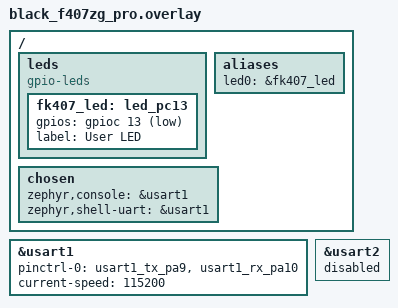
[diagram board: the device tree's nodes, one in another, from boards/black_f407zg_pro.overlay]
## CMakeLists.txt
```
cmake_minimum_required(VERSION 3.20.0)

find_package(Zephyr REQUIRED HINTS $ENV{ZEPHYR_BASE})
project(fk407m2_blinky_uart_usbh_msc)

# This app links the SAME shared app/ + external/ sources (two levels up,
# repo root) as the host/freertos/threadx targets - only this directory's
# own concrete adapters (OSAL: osal.c, cfuture_sync_ops.c; PAL: log_sink_impl.c,
# time_source_impl.c, board_led.c, usb_host_irq.c, hal_shim.c, crash_dump_zephyr.c)
# and src/main.c (composition root) are Zephyr-specific. usb_host.c/usbh_conf.c
# used to be a near-duplicate per target too; they're shared app/ sources now -
# only IRQ registration (usb_host_irq.c) and the heap (osal.c's
# osal_malloc()/osal_free()) still differ per platform.
set(APP_ROOT ${CMAKE_CURRENT_SOURCE_DIR}/../..)
set(SHARED_APP_DIR ${APP_ROOT}/app)
set(SHARED_EXTERNAL_DIR ${APP_ROOT}/external)
set(OSAL_DIR ${CMAKE_CURRENT_SOURCE_DIR}/osal)
set(PAL_DIR ${CMAKE_CURRENT_SOURCE_DIR}/pal)

# Zephyr's own hal_stm32 module vendors this SoC's HAL/LL sources but only
# compiles the subset its own drivers reference (see CLAUDE.md for why). We
# add exactly the files this app's USB Host MSC + FatFS showcase needs
# directly to `app`, alongside the app's own sources.
set(HAL_STM32_F4XX_DIR $ENV{ZEPHYR_BASE}/../modules/hal/stm32/stm32cube/stm32f4xx)

target_sources(app PRIVATE
    src/main.c
    osal/src/osal.c
    osal/src/cfuture_sync_ops.c
    pal/src/board_led.c
    pal/src/log_sink_impl.c
    pal/src/time_source_impl.c
    pal/src/hal_shim.c
    pal/src/usb_host_irq.c
    pal/src/crash_dump_zephyr.c

    # Shared OS-agnostic application layer (identical across every target)
    ${SHARED_APP_DIR}/src/core/app.c
    ${SHARED_APP_DIR}/src/core/app_threads.c
    ${SHARED_APP_DIR}/src/core/logger.c
    ${SHARED_APP_DIR}/src/diagnostics/app_task_trace.c
    ${SHARED_APP_DIR}/src/diagnostics/blinky_task.c
    ${SHARED_APP_DIR}/src/diagnostics/cfuture_selftest.c
    ${SHARED_APP_DIR}/src/diagnostics/crash_dump.c
    ${SHARED_APP_DIR}/src/storage/storage_service.c
    ${SHARED_APP_DIR}/src/storage/client_tasks.c
    ${SHARED_APP_DIR}/src/storage/storage_demo.c
    ${SHARED_APP_DIR}/src/storage/fatfs_diskio.c
    ${SHARED_APP_DIR}/src/storage/fatfs_time.c
    ${SHARED_APP_DIR}/src/usb/usbh_msc_disk.c
    ${SHARED_APP_DIR}/src/usb/usb_host.c
    ${SHARED_APP_DIR}/src/usb/usbh_conf.c

    # Vendored ST HAL (HCD + GPIO + Cortex/NVIC - see CLAUDE.md)
    ${HAL_STM32_F4XX_DIR}/drivers/src/stm32f4xx_hal_hcd.c
    ${HAL_STM32_F4XX_DIR}/drivers/src/stm32f4xx_ll_usb.c
    ${HAL_STM32_F4XX_DIR}/drivers/src/stm32f4xx_hal_gpio.c
    ${HAL_STM32_F4XX_DIR}/drivers/src/stm32f4xx_hal_cortex.c

    # Shared vendored ST USB Host Core + MSC class library
    ${SHARED_EXTERNAL_DIR}/usb_host_lib/Core/Src/usbh_core.c
    ${SHARED_EXTERNAL_DIR}/usb_host_lib/Core/Src/usbh_ctlreq.c
    ${SHARED_EXTERNAL_DIR}/usb_host_lib/Core/Src/usbh_ioreq.c
    ${SHARED_EXTERNAL_DIR}/usb_host_lib/Core/Src/usbh_pipes.c
    ${SHARED_EXTERNAL_DIR}/usb_host_lib/Class/MSC/Src/usbh_msc.c
    ${SHARED_EXTERNAL_DIR}/usb_host_lib/Class/MSC/Src/usbh_msc_bot.c
    ${SHARED_EXTERNAL_DIR}/usb_host_lib/Class/MSC/Src/usbh_msc_scsi.c

    # Shared vendored Chan's FatFS (_USE_LFN == 0 in this project's
    # ffconf.h - no long-filename support, so option/ffunicode.c is not needed)
    ${SHARED_EXTERNAL_DIR}/fatfs/src/ff.c

    # Shared vendored libcfuture
    ${SHARED_EXTERNAL_DIR}/cfuture/src/cfuture.c
    ${SHARED_EXTERNAL_DIR}/cfuture/src/cfuture_pal.c
)

target_include_directories(app PRIVATE
    ${OSAL_DIR}/include
    ${PAL_DIR}/include
    ${SHARED_APP_DIR}/include
    ${SHARED_APP_DIR}/include/osal
    ${SHARED_APP_DIR}/include/pal
    ${SHARED_APP_DIR}/include/core
    ${SHARED_APP_DIR}/include/diagnostics
    ${SHARED_APP_DIR}/include/storage
    ${SHARED_APP_DIR}/include/usb
    ${SHARED_EXTERNAL_DIR}/cfuture/include
    ${SHARED_EXTERNAL_DIR}/fatfs
    ${SHARED_EXTERNAL_DIR}/fatfs/src
    ${SHARED_EXTERNAL_DIR}/usb_host_lib/Core/Inc
    ${SHARED_EXTERNAL_DIR}/usb_host_lib/Class/MSC/Inc
    ${HAL_STM32_F4XX_DIR}/drivers/include
    ${HAL_STM32_F4XX_DIR}/soc
    $ENV{ZEPHYR_BASE}/../modules/hal/cmsis/CMSIS/Core/Include
)

target_compile_definitions(app PRIVATE
    STM32F407xx
    USE_HAL_DRIVER
)
```

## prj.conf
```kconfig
CONFIG_GPIO=y
CONFIG_SERIAL=y
CONFIG_CONSOLE=y
CONFIG_UART_CONSOLE=y
CONFIG_PRINTK=y

# osal_zephyr.c dynamically allocates per-task stacks (k_thread_stack_alloc)
# and per-queue k_msgq control blocks/buffers (k_malloc/k_msgq_alloc_init) -
# mirrors osal_threadx.c's own use of ThreadX's byte pool for the same
# purpose. Raw stack requests alone total ~36.9KB (USB Host process task
# 4096B + storage service task 8192B + 4 client tasks x 6144B each), plus a
# k_msgq buffer (StorageRequest is ~530B x queue depth 8) and per-allocation
# heap/MPU-guard overhead on top. 40960 was NOT enough - confirmed on real
# hardware: the 6th task (AbaIso/scenario4) failed to allocate its stack and
# logged "storageDemo: task creation failed", silently leaving that one
# scenario never running while the other three passed - same "measure on
# real hardware, don't trust a guess" lesson the FreeRTOS/ThreadX ports
# already learned the hard way for their own stack/heap sizing. Sized with
# real headroom now, not just past the observed failure point.
CONFIG_DYNAMIC_THREAD=y
CONFIG_DYNAMIC_THREAD_ALLOC=y
CONFIG_HEAP_MEM_POOL_SIZE=65536

# cfuture_osal_zephyr.c's event/wait synchronization.
CONFIG_EVENTS=y

# main's own stack (Logger + LED loop) plus the app's other static/system
# threads - default is too tight once the storage showcase's tasks are
# also live.
CONFIG_MAIN_STACK_SIZE=2048

# HAL_HCD_MspInit registers OTG_FS_IRQn (67) via Zephyr's own IRQ_CONNECT()
# at runtime from usbh_conf_zephyr.c. Zephyr auto-sizes its ISR table
# (CONFIG_NUM_IRQS, a locked `configdefault` - not overridable from here)
# from the highest IRQ number actually referenced in devicetree; the board
# overlay deliberately leaves usbotg_fs's DT node "okay" (see its comment)
# specifically so IRQ67 stays visible to that auto-sizing.

# assert_param()/HAL_ASSERT-style checks are compiled out (USE_FULL_ASSERT
# not defined in stm32f4xx_hal_conf.h) - no CONFIG_ASSERT dependency from
# the vendored HAL/USB Host/FatFS code.
```

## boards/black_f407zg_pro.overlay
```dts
/*
 * Overlay adapting the black_f407zg_pro board definition (same chip,
 * STM32F407ZGT6, as our FK407M2-ZGT6 board) to this board's real wiring:
 * user LED on PC13 (active-low) instead of PF9/PF10, and USART1 on
 * PA9(TX)/PA10(RX) instead of PB6/PB7.
 */

/ {
	leds {
		compatible = "gpio-leds";
		fk407_led: led_pc13 {
			gpios = <&gpioc 13 GPIO_ACTIVE_LOW>;
			label = "User LED";
		};
	};

	aliases {
		led0 = &fk407_led;
	};

	chosen {
		zephyr,console = &usart1;
		zephyr,shell-uart = &usart1;
	};
};

&usart1 {
	pinctrl-0 = <&usart1_tx_pa9 &usart1_rx_pa10>;
	pinctrl-names = "default";
	current-speed = <115200>;
	status = "okay";
};

&usart2 {
	status = "disabled";
};

/* This app drives USB_OTG_FS directly in Host mode via a vendored ST HAL
 * HCD driver + USB Host MSC library (see app/CMakeLists.txt and
 * app/src/usbh_conf_zephyr.c), bypassing Zephyr's own native USB stack
 * entirely (it has no USB Host MSC class driver - see CLAUDE.md).
 *
 * The vendor board's usbotg_fs node is deliberately left "okay" (its
 * upstream default), NOT disabled: Zephyr only actually compiles/inits its
 * own Device-mode UDC driver for this node when CONFIG_USB_DEVICE_STACK (or
 * similar) is enabled, which this app's prj.conf never does - so leaving it
 * "okay" costs nothing at runtime, but keeps IRQ67 visible to devicetree,
 * which Zephyr's NUM_IRQS auto-sizing (soc/st/stm32/Kconfig.defconfig)
 * depends on to size the ISR table large enough for our own manual
 * IRQ_CONNECT(OTG_FS_IRQn, ...) in usbh_conf_zephyr.c. Disabling this node
 * shrinks NUM_IRQS below 67 and breaks that IRQ_CONNECT() at build time -
 * do not disable it. */
```

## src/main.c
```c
#include <zephyr/kernel.h>
#include <zephyr/sys/printk.h>

#include "app.h"
#include "board_led.h"
#include "cfuture_sync_ops.h"
#include "crash_dump.h"
#include "log_sink_impl.h"
#include "usb_host.h"
#include "usbh_msc_disk.h"
#include "time_source_impl.h"

enum
{
    kUsbHostProcessStackBytes = 4096U,
    kWatchdogStackBytes = 128U * 4U * 4U,
};

static PalStorage s_mscStorage;

int main(void)
{
    /* First thing, before anything else can fault: route MemManage/Bus/
     * UsageFault to their own handlers and arm the independent watchdog -
     * see crash_dump.h's own doc comment. Zephyr's own fault path
     * (k_sys_fatal_error_handler(), pal/src/crash_dump_zephyr.c) still
     * gets first look at any fault regardless; this only affects the raw
     * CPU vector routing / watchdog arming, both boot-time, both orthogonal
     * to that. */
    crashDumpEarlyInit();

    AppDependencies deps = {0};

    if (!board_led_init(&deps.led))
    {
        printk("[ERROR] LED device not ready\r\n");
        crashDumpHalt();
    }

    log_sink_init(&deps.logSink);
    time_source_init(&deps.timeSource);

    usbhMscDiskInit(&s_mscStorage);
    deps.storage = s_mscStorage;

    deps.cfutureSyncOps = cfuture_sync_ops_get();

    /* USBH_USE_OS=0 on this target (usbh_conf.h) - nothing else drives the
     * USB Host state machine forward, so appRun() must start a thread that
     * pumps USBH_Process() forever. */
    deps.usbHostProcessEntry = usbHostProcessTaskEntry;
    deps.usbHostProcessContext = NULL;
    deps.usbHostProcessStackBytes = kUsbHostProcessStackBytes;

    deps.watchdogTaskEntry = crashDumpWatchdogTaskEntry;
    deps.watchdogTaskStackBytes = kWatchdogStackBytes;

    if (!appRun(&deps))
    {
        crashDumpHalt();
    }

    return 0;
}
```
